# RN831X_RN861X_MCU register map
File version: v0.0.1
CPU: RN831X_RN861X_MCU r1p0, little endian, MPU, no FPU
Registers are 32-bit, read-write, reset 0x0 unless marked. A register's access mark holds for its fields unless they carry their own. Offsets are from the block's base; [hi:lo] are bit positions; {n}, {i} and the like mark numbered series; <NAME> marks a mode.

## USART0_CORE0 — USART0 Module core0
Base 0x20024000
Same registers: USART1_CORE0 0x20028000, USART0_CORE1 0xA0024000, USART1_CORE1 0xA0028000
0x00 TXDATA access not given — Transmit Data Register
  [8:0] TXDATA — Data to transmit
0x04 RXDATA ro — Receive Data Register
  [8:0] RXDATA — Received data
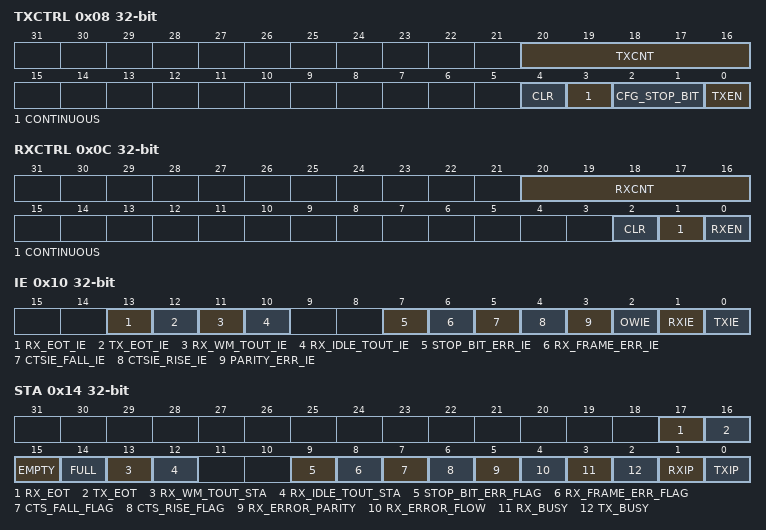
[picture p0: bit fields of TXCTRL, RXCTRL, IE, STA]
0x08 TXCTRL access per field — Transmit Control Register
  [20:16] TXCNT rw — Transmit watermark level
  [4] CLR wo — Clear TX channel and stop & clear transmission
  [3] CONTINUOUS rw — GDMA reload mode
  [2:1] CFG_STOP_BIT rw — Stop bit length
    0=0_5 (0.5 stop bit); 1=1 stop bit; 2=1_5 (1.5 stop bits); 3=2 stop bits
  [0] TXEN rw — Transmit enable
0x0C RXCTRL — Receive Control Register
  [20:16] RXCNT — Receive watermark level
  [2] CLR — Clear RX channel
  [1] CONTINUOUS — GDMA reload mode
  [0] RXEN — Receive enable
0x10 IE — Interrupt Enable Register
  [13] RX_EOT_IE — RX transfer complete interrupt enable
  [12] TX_EOT_IE — TX transfer complete interrupt enable
  [11] RX_WM_TOUT_IE — RX watermark timeout interrupt enable
  [10] RX_IDLE_TOUT_IE — RX idle timeout interrupt enable
  [7] STOP_BIT_ERR_IE — Stop bit error interrupt
  [6] RX_FRAME_ERR_IE — RX frame error interrupt enable
  [5] CTSIE_FALL_IE — CTS falling edge interrupt enable
  [4] CTSIE_RISE_IE — CTS rising edge interrupt enable
  [3] PARITY_ERR_IE — RX parity error interrupt enable
  [2] OWIE — RX overflow interrupt enable
  [1] RXIE — RX watermark interrupt enable
  [0] TXIE — TX watermark interrupt enable
0x14 STA access per field — Status Register
  [17] RX_EOT rw write-1-clears — RX transfer complete
  [16] TX_EOT rw write-1-clears — TX transfer complete
  [15] EMPTY ro — RX FIFO empty
  [14] FULL ro — TX FIFO full
  [13] RX_WM_TOUT_STA rw write-1-clears — RX watermark timeout status
  [12] RX_IDLE_TOUT_STA rw write-1-clears — RX idle timeout status
  [9] STOP_BIT_ERR_FLAG rw write-1-clears — Stop bit length mismatch error
  [8] RX_FRAME_ERR_FLAG rw write-1-clears — Stop bit low-level error, RX Frame Error Flag
  [7] CTS_FALL_FLAG rw write-1-clears — CTS falling edge detected
  [6] CTS_RISE_FLAG rw write-1-clears — CTS rising edge detected
  [5] RX_ERROR_PARITY rw write-1-clears — RX parity error
  [4] RX_ERROR_FLOW rw write-1-clears — RX overflow error
  [3] RX_BUSY ro
  [2] TX_BUSY ro
  [1] RXIP ro — RX interrupt pending (FIFO level > RXCNT)
  [0] TXIP ro — TX interrupt pending (FIFO level < TXCNT)
0x18 DIV access not given — Baud Rate Divider Register
  [20:0] BAUD_DIV — Fractional mode uses bits [20:3] for integer, [2:0] for fraction (0.000-0.875). Must be equal or greater than 2.
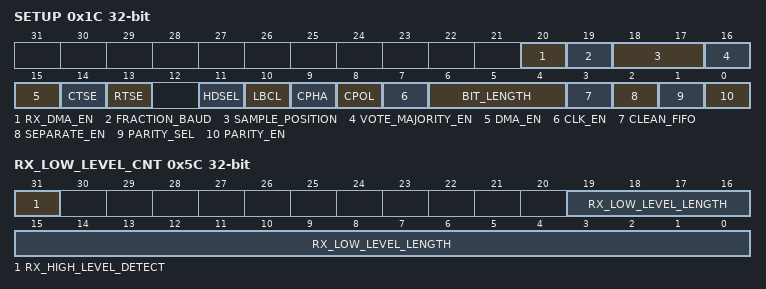
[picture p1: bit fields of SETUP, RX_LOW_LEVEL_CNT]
0x1C SETUP — Configuration Register
  [20] RX_DMA_EN — RX DMA mode (when SEPARATE_EN=1)
  [19] FRACTION_BAUD — Fractional baud enable
  [18:17] SAMPLE_POSITION — Sampling point
    0=SPREAD (Sampling point is spread); 1=DOWN (Sampling point is down); 2=UP (Sampling point is up)
  [16] VOTE_MAJORITY_EN — 2/3 majority vote
  [15] DMA_EN — TX DMA mode (or global if SEPARATE_EN=0)
  [14] CTSE — CTS flow control
  [13] RTSE — RTS flow control
  [11] HDSEL — Half-duplex mode
  [10] LBCL — Last bit clock pulse
    0=NO_OUTPUT (No Output on CK pin); 1=OUTPUT (Output on CK pin)
  [9] CPHA — Clock phase
    0=1EDGE (First edge); 1=2EDGE (Second edge)
  [8] CPOL — Clock polarity
    0=LOW (Idle low); 1=HIGH (Idle high)
  [7] CLK_EN — CK pin enable
  [6:4] BIT_LENGTH — Data bits
    {v}={v+5}B ({v+5} bits data length) (v=0..4)
  [3] CLEAN_FIFO — Clear RX FIFO
  [2] SEPARATE_EN — Separate TX/RX DMA control
  [1] PARITY_SEL — Parity type
    0=EVEN (Even parity); 1=ODD (Odd parity)
  [0] PARITY_EN — Parity enable
0x24 RX_SIZE access not given — RX Transfer Size Register
  [19:0] RX_SIZE
0x30 TX_SIZE access not given — TX Transfer Size Register
  [19:0] TX_SIZE
0x44 RX_IDLE access not given — RX Idle Timeout Register
  [31:0] IDLE_TOUT_NUM — Timeout value for idle detection
0x48 RX_WM access not given — RX Watermark Timeout Register
  [31:0] WM_TOUT_NUM — Timeout value for RX watermark
0x4C RX_FIFO_LEFT_ENTRY ro — RX FIFO Free Space
  [4:0] LEFT_ENTRY — Free entries in RX FIFO
0x50 TX_FIFO_LEFT_ENTRY ro — TX FIFO Free Space
  [4:0] LEFT_ENTRY — Free entries in TX FIFO
0x5C RX_LOW_LEVEL_CNT — RX Low-Level Duration
  [31] RX_HIGH_LEVEL_DETECT — Low-Level rising edge detected
  [19:0] RX_LOW_LEVEL_LENGTH — Low-level duration in clock cycles
